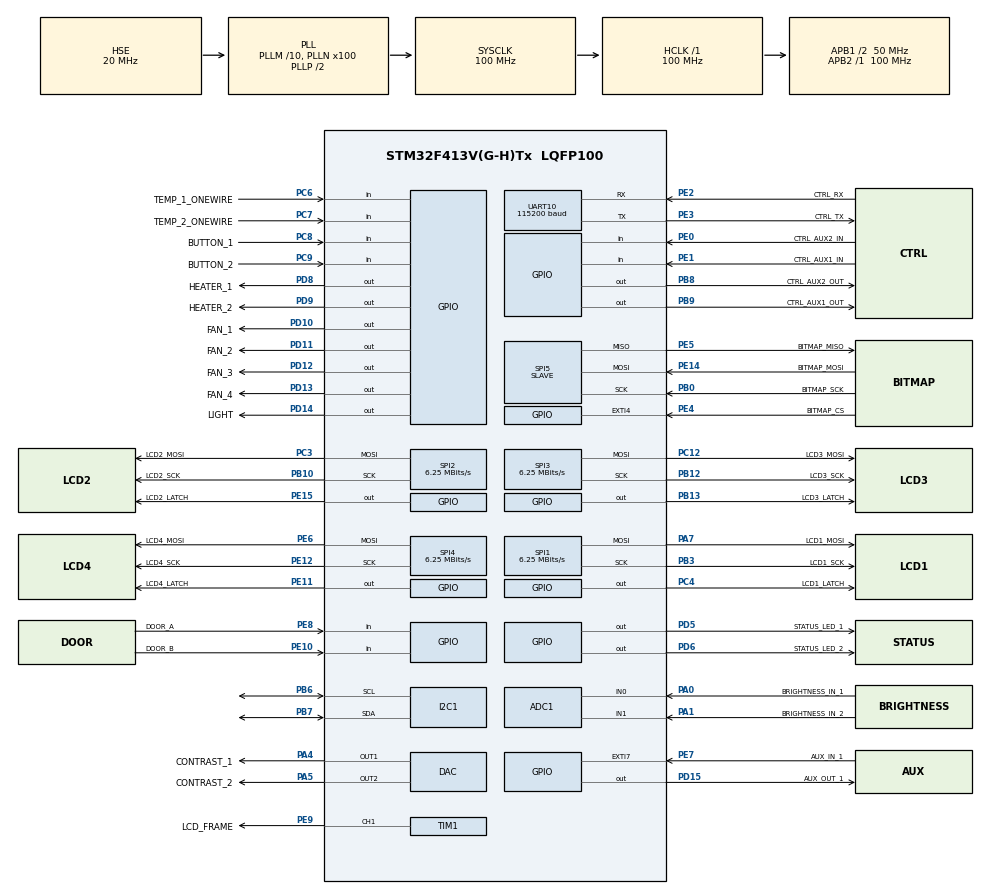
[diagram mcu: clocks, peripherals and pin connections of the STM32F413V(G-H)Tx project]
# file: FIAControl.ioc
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Dma.SPI3_TX.2.MemInc=DMA_MINC_ENABLE
VP_TIM5_VS_ClockSourceINT.Mode=Internal
PD12.GPIO_Label=FAN_3
Dma.SPI1_TX.0.PeriphInc=DMA_PINC_DISABLE
SPI3.Direction=SPI_DIRECTION_2LINES
SPI4.VirtualType=VM_MASTER
SPI3.VirtualType=VM_MASTER
NVIC.I2C1_EV_IRQn=true\:0\:0\:false\:false\:true\:true\:true
Dma.UART10_RX.6.Direction=DMA_PERIPH_TO_MEMORY
SPI1.VirtualType=VM_MASTER
SPI2.VirtualType=VM_MASTER
VP_ADC1_TempSens_Input.Mode=IN-TempSens
PB10.Mode=TX_Only_Simplex_Unidirect_Master
PC12.Signal=SPI3_MOSI
PE8.GPIO_PuPd=GPIO_PULLUP
Dma.SPI5_RX.4.Priority=DMA_PRIORITY_VERY_HIGH
PC6.GPIO_Label=TEMP_1_ONEWIRE
PE10.GPIO_PuPd=GPIO_PULLUP
Dma.SPI5_RX.4.MemDataAlignment=DMA_MDATAALIGN_BYTE
PB13.Signal=GPIO_Output
PD6.GPIO_Label=STATUS_LED_2
PE6.GPIO_Label=LCD4_MOSI
Dma.SPI5_RX.4.FIFOMode=DMA_FIFOMODE_DISABLE
RCC.SYSCLKSource=RCC_SYSCLKSOURCE_PLLCLK
Dma.UART10_RX.6.Instance=DMA2_Stream0
UART10.BaudRate=115200
NVIC.TIM5_IRQn=true\:2\:0\:true\:false\:true\:true\:true
SPI1.Direction=SPI_DIRECTION_2LINES
Dma.UART10_TX.7.PeriphDataAlignment=DMA_PDATAALIGN_BYTE
PE2.Mode=Asynchronous
RCC.APB2TimFreq_Value=100000000
Dma.SPI3_TX.2.PeriphDataAlignment=DMA_PDATAALIGN_BYTE
PB6.Signal=I2C1_SCL
ADC1.Channel-2\#ChannelRegularConversion=ADC_CHANNEL_TEMPSENSOR
PC7.Signal=GPIO_Input
PB6.Mode=I2C
SPI1.CalculateBaudRate=6.25 MBits/s
PC3.Signal=SPI2_MOSI
PD8.Signal=GPIO_Output
Dma.UART10_TX.7.Priority=DMA_PRIORITY_LOW
PE5.Signal=SPI5_MISO
PE1.Signal=GPIO_Input
PB3.Mode=TX_Only_Simplex_Unidirect_Master
ADC1.ScanConvMode=ENABLE
PB12.GPIO_Label=LCD3_SCK
PC4.GPIO_Label=LCD1_LATCH
TIM1.Channel-PWM\ Generation1\ CH1=TIM_CHANNEL_1
PE9.Signal=S_TIM1_CH1
PE4.GPIO_Label=BITMAP_CS
SPI2.CalculateBaudRate=6.25 MBits/s
PE2.Signal=UART10_RX
TIM4.Period=50000
Dma.SPI3_TX.2.Direction=DMA_MEMORY_TO_PERIPH
NVIC.I2C1_ER_IRQn=true\:0\:0\:false\:false\:true\:true\:true
PE10.Signal=GPIO_Input
ADC1.SamplingTime-0\#ChannelRegularConversion=ADC_SAMPLETIME_480CYCLES
PA0.Signal=ADCx_IN0
Dma.SPI2_TX.1.FIFOMode=DMA_FIFOMODE_DISABLE
Dma.SPI1_TX.0.Mode=DMA_NORMAL
Mcu.Package=LQFP100
PB9.Signal=GPIO_Output
TIM2.Prescaler=99
SPI2.Mode=SPI_MODE_MASTER
SPI3.Mode=SPI_MODE_MASTER
PD12.Signal=GPIO_Output
PE12.GPIO_Label=LCD4_SCK
PC6.GPIO_PuPd=GPIO_PULLUP
Dma.SPI2_TX.1.Instance=DMA1_Stream4
NVIC.DMA2_Stream2_IRQn=true\:0\:0\:true\:false\:true\:false\:true
RCC.APB1TimFreq_Value=100000000
Dma.ADC1.5.MemDataAlignment=DMA_MDATAALIGN_WORD
TIM1.Period=LCD_FR_INTERVAL
PE10.GPIO_Label=DOOR_B
PD6.GPIO_ModeDefaultOutputPP=GPIO_MODE_OUTPUT_OD
PA4.GPIO_Label=CONTRAST_1
ADC1.EOCSelection=ADC_EOC_SINGLE_CONV
PD15.Signal=GPIO_Output
SPI5.VirtualType=VM_SLAVE
Dma.UART10_RX.6.Priority=DMA_PRIORITY_HIGH
NVIC.UART10_IRQn=true\:1\:0\:true\:false\:true\:true\:true
PE12.Mode=TX_Only_Simplex_Unidirect_Master
Dma.SPI2_TX.1.MemInc=DMA_MINC_ENABLE
NVIC.EXTI4_IRQn=true\:0\:0\:false\:false\:true\:true\:true
Dma.SPI4_TX.3.MemDataAlignment=DMA_MDATAALIGN_BYTE
Dma.UART10_RX.6.Mode=DMA_CIRCULAR
ADC1.Rank-0\#ChannelRegularConversion=1
PD9.GPIO_Label=HEATER_2
PH1\ -\ OSC_OUT.Mode=HSE-External-Oscillator
PC6.Signal=GPIO_Input
Dma.UART10_RX.6.MemDataAlignment=DMA_MDATAALIGN_BYTE
SPI1.CLKPhase=SPI_PHASE_2EDGE
NVIC.DMA2_Stream1_IRQn=true\:0\:0\:true\:false\:true\:false\:true
RCC.APB1CLKDivider=RCC_HCLK_DIV2
Dma.SPI4_TX.3.FIFOMode=DMA_FIFOMODE_DISABLE
PD10.Signal=GPIO_Output
PB8.GPIO_Label=CTRL_AUX2_OUT
Dma.SPI1_TX.0.FIFOMode=DMA_FIFOMODE_DISABLE
PE8.GPIO_Label=DOOR_A
PC7.GPIO_PuPd=GPIO_PULLUP
Dma.UART10_RX.6.FIFOMode=DMA_FIFOMODE_DISABLE
PE9.GPIO_Label=LCD_FRAME
PB10.Signal=SPI2_SCK
Dma.UART10_TX.7.Direction=DMA_MEMORY_TO_PERIPH
PA5.Signal=COMP_DAC2_group
PC12.Mode=TX_Only_Simplex_Unidirect_Master
PH1\ -\ OSC_OUT.Signal=RCC_OSC_OUT
PE1.GPIO_Label=CTRL_AUX1_IN
Dma.SPI5_RX.4.Instance=DMA2_Stream3
NVIC.TIM3_IRQn=true\:2\:0\:true\:false\:true\:true\:true
PE14.Signal=SPI5_MOSI
PE6.Mode=TX_Only_Simplex_Unidirect_Master
PE15.Signal=GPIO_Output
Dma.SPI2_TX.1.PeriphDataAlignment=DMA_PDATAALIGN_BYTE
PE8.Signal=GPIO_Input
SPI1.Mode=SPI_MODE_MASTER
Dma.SPI2_TX.1.Priority=DMA_PRIORITY_VERY_HIGH
Dma.UART10_TX.7.Instance=DMA2_Stream5
PA1.GPIO_Label=BRIGHTNESS_IN_2
PC9.GPIO_PuPd=GPIO_PULLUP
Dma.SPI1_TX.0.Instance=DMA2_Stream2
ADC1.DMAContinuousRequests=ENABLE
TIM2.Period=65535
UART10.VirtualMode=Asynchronous
PA13.Mode=Serial_Wire
UART10.Mode=MODE_TX_RX
Dma.UART10_TX.7.Mode=DMA_NORMAL
NVIC.DMA2_Stream4_IRQn=true\:0\:0\:true\:false\:true\:false\:true
PC7.GPIO_Label=TEMP_2_ONEWIRE
PC8.GPIO_PuPd=GPIO_PULLUP
PA4.Signal=COMP_DAC1_group
ADC1.SamplingTime-1\#ChannelRegularConversion=ADC_SAMPLETIME_480CYCLES
ADC1.master=1
PA5.GPIO_Label=CONTRAST_2
Dma.SPI5_RX.4.PeriphDataAlignment=DMA_PDATAALIGN_BYTE
PD11.Signal=GPIO_Output
PE5.GPIO_Label=BITMAP_MISO
PC12.GPIO_Label=LCD3_MOSI
ADC1.Rank-1\#ChannelRegularConversion=2
Dma.SPI4_TX.3.Instance=DMA2_Stream1
Dma.ADC1.5.PeriphDataAlignment=DMA_PDATAALIGN_WORD
ProjectManager.HeapSize=0x200
Dma.SPI3_TX.2.PeriphInc=DMA_PINC_DISABLE
Dma.SPI4_TX.3.Direction=DMA_MEMORY_TO_PERIPH
SPI4.CLKPhase=SPI_PHASE_2EDGE
VP_TIM4_VS_ClockSourceINT.Mode=Internal
NVIC.PriorityGroup=NVIC_PRIORITYGROUP_4
PE3.Signal=UART10_TX
PC3.GPIO_Label=LCD2_MOSI
PD5.GPIO_ModeDefaultOutputPP=GPIO_MODE_OUTPUT_OD
Dma.ADC1.5.FIFOMode=DMA_FIFOMODE_DISABLE
PB0.Signal=SPI5_SCK
Dma.UART10_RX.6.PeriphInc=DMA_PINC_DISABLE
Dma.ADC1.5.Instance=DMA2_Stream4
Dma.SPI2_TX.1.MemDataAlignment=DMA_MDATAALIGN_BYTE
Dma.SPI5_RX.4.Direction=DMA_PERIPH_TO_MEMORY
Dma.UART10_TX.7.FIFOMode=DMA_FIFOMODE_DISABLE
Mcu.Family=STM32F4
PC3.Mode=TX_Only_Simplex_Unidirect_Master
Dma.SPI1_TX.0.MemInc=DMA_MINC_ENABLE
PE7.GPIO_PuPd=GPIO_PULLUP
RCC.CortexFreq_Value=100000000
Dma.UART10_TX.7.PeriphInc=DMA_PINC_DISABLE
Dma.SPI3_TX.2.Instance=DMA1_Stream5
ADC1.ContinuousConvMode=ENABLE
PE11.GPIO_Label=LCD4_LATCH
VP_IWDG_VS_IWDG.Mode=IWDG_Activate
SPI4.Direction=SPI_DIRECTION_2LINES
PA0.GPIO_Label=BRIGHTNESS_IN_1
Dma.SPI2_TX.1.PeriphInc=DMA_PINC_DISABLE
PB0.GPIO_Label=BITMAP_SCK
TIM1.Pulse-PWM\ Generation1\ CH1=LCD_FR_INTERVAL/2
PB13.GPIO_Label=LCD3_LATCH
Dma.SPI3_TX.2.Mode=DMA_NORMAL
NVIC.DMA1_Stream4_IRQn=true\:0\:0\:true\:false\:true\:false\:true
ProjectManager.StackSize=0x400
SH.COMP_DAC2_group.0=DAC_OUT2,DAC_OUT2
Dma.SPI5_RX.4.MemInc=DMA_MINC_ENABLE
PD13.Signal=GPIO_Output
TIM1.Prescaler=199
SPI1.CLKPolarity=SPI_POLARITY_LOW
Dma.SPI4_TX.3.PeriphDataAlignment=DMA_PDATAALIGN_BYTE
PH0\ -\ OSC_IN.Signal=RCC_OSC_IN
SPI4.Mode=SPI_MODE_MASTER
PD11.GPIO_Label=FAN_2
RCC.HCLKFreq_Value=100000000
TIM3.Period=625
NVIC.DMA2_Stream0_IRQn=true\:0\:0\:true\:false\:true\:false\:true
RCC.AHBFreq_Value=100000000
SPI2.BaudRatePrescaler=SPI_BAUDRATEPRESCALER_8
ADC1.Channel-0\#ChannelRegularConversion=ADC_CHANNEL_0
RCC.HSE_VALUE=20000000
Dma.SPI4_TX.3.PeriphInc=DMA_PINC_DISABLE
ADC1.Rank-2\#ChannelRegularConversion=3
PA14.Mode=Serial_Wire
TIM3.Prescaler=9999
PB7.Signal=I2C1_SDA
SH.ADCx_IN0.0=ADC1_IN0,IN0
Dma.SPI3_TX.2.Priority=DMA_PRIORITY_VERY_HIGH
PE4.Signal=GPXTI4
SPI4.BaudRatePrescaler=SPI_BAUDRATEPRESCALER_16
Dma.SPI3_TX.2.FIFOMode=DMA_FIFOMODE_DISABLE
PD13.GPIO_Label=FAN_4
PB12.Mode=TX_Only_Simplex_Unidirect_Master
Dma.SPI2_TX.1.Mode=DMA_NORMAL
PD5.GPIO_Label=STATUS_LED_1
IWDG.Reload=4095
SPI2.CLKPhase=SPI_PHASE_2EDGE
PE0.GPIO_Label=CTRL_AUX2_IN
SH.ADCx_IN1.0=ADC1_IN1,IN1
Dma.ADC1.5.PeriphInc=DMA_PINC_DISABLE
Dma.Request2=SPI3_TX
Dma.Request1=SPI2_TX
Dma.SPI5_RX.4.PeriphInc=DMA_PINC_DISABLE
Dma.Request4=SPI5_RX
Dma.UART10_TX.7.MemInc=DMA_MINC_ENABLE
Dma.Request3=SPI4_TX
Dma.Request6=UART10_RX
Dma.Request5=ADC1
SPI2.Direction=SPI_DIRECTION_2LINES
Dma.Request7=UART10_TX
PE7.Signal=GPXTI7
Dma.UART10_RX.6.MemInc=DMA_MINC_ENABLE
PD6.Signal=GPIO_Output
Dma.Request0=SPI1_TX
SPI1.BaudRatePrescaler=SPI_BAUDRATEPRESCALER_16
PE2.GPIO_Label=CTRL_RX
PE3.Mode=Asynchronous
VP_TIM3_VS_ClockSourceINT.Mode=Internal
PB3.GPIO_Label=LCD1_SCK
RCC.PLLSourceVirtual=RCC_PLLSOURCE_HSE
SH.COMP_DAC1_group.0=DAC_OUT1,DAC_OUT1
PD15.GPIO_Label=AUX_OUT_1
TIM3.CounterMode=TIM_COUNTERMODE_UP
PA7.Mode=TX_Only_Simplex_Unidirect_Master
PB9.GPIO_Label=CTRL_AUX1_OUT
PC9.GPIO_Label=BUTTON_2
Dma.SPI4_TX.3.MemInc=DMA_MINC_ENABLE
PC8.Signal=GPIO_Input
PC4.Signal=GPIO_Output
PE4.GPIO_ModeDefaultEXTI=GPIO_MODE_IT_RISING_FALLING
Dma.SPI4_TX.3.Mode=DMA_NORMAL
PE14.GPIO_Label=BITMAP_MOSI
PD9.Signal=GPIO_Output
PD5.Signal=GPIO_Output
Dma.SPI4_TX.3.Priority=DMA_PRIORITY_VERY_HIGH
Dma.ADC1.5.Direction=DMA_PERIPH_TO_MEMORY
SPI5.Mode=SPI_MODE_SLAVE
ADC1.SamplingTime-2\#ChannelRegularConversion=ADC_SAMPLETIME_480CYCLES
TIM1.ClockDivision=TIM_CLOCKDIVISION_DIV1
PD8.GPIO_Label=HEATER_1
PC8.GPIO_Label=BUTTON_1
PA13.Signal=SYS_JTMS-SWDIO
PH0\ -\ OSC_IN.Mode=HSE-External-Oscillator
SH.S_TIM1_CH1.0=TIM1_CH1,PWM Generation1 CH1
PE15.GPIO_Label=LCD2_LATCH
ProjectManager.TargetToolchain=Makefile
PB10.GPIO_Label=LCD2_SCK
NVIC.DMA1_Stream5_IRQn=true\:0\:0\:true\:false\:true\:false\:true
Dma.SPI1_TX.0.PeriphDataAlignment=DMA_PDATAALIGN_BYTE
Dma.SPI1_TX.0.Direction=DMA_MEMORY_TO_PERIPH
Dma.UART10_RX.6.PeriphDataAlignment=DMA_PDATAALIGN_BYTE
ADC1.Channel-1\#ChannelRegularConversion=ADC_CHANNEL_1
RCC.USBFreq_Value=100000000
PD10.GPIO_Label=FAN_1
NVIC.DMA2_Stream3_IRQn=true\:0\:0\:true\:false\:true\:false\:true
TIM4.Prescaler=9999
PE11.Signal=GPIO_Output
PA1.Signal=ADCx_IN1
Dma.ADC1.5.Priority=DMA_PRIORITY_MEDIUM
PB0.Mode=Full_Duplex_Slave
board=custom
SPI3.CLKPhase=SPI_PHASE_2EDGE
Dma.SPI2_TX.1.Direction=DMA_MEMORY_TO_PERIPH
RCC.VCOOutputFreq_Value=200000000
RCC.APB2Freq_Value=100000000
SPI3.CalculateBaudRate=6.25 MBits/s
UART10.OverSampling=UART_OVERSAMPLING_8
VP_TIM2_VS_ClockSourceINT.Mode=Internal
PE14.Mode=Full_Duplex_Slave
Dma.SPI3_TX.2.MemDataAlignment=DMA_MDATAALIGN_BYTE
PE5.Mode=Full_Duplex_Slave
NVIC.DMA2_Stream5_IRQn=true\:0\:0\:false\:false\:true\:false\:true
SPI3.BaudRatePrescaler=SPI_BAUDRATEPRESCALER_8
PE7.GPIO_ModeDefaultEXTI=GPIO_MODE_IT_RISING_FALLING
SPI4.CalculateBaudRate=6.25 MBits/s
PD14.GPIO_Label=LIGHT
PE6.Signal=SPI4_MOSI
ADC1.NbrOfConversion=3
Mcu.Name=STM32F413V(G-H)Tx
PE0.Signal=GPIO_Input
PE7.GPIO_Label=AUX_IN_1
PE12.Signal=SPI4_SCK
PD14.Signal=GPIO_Output
PB3.Signal=SPI1_SCK
RCC.SYSCLKFreq_VALUE=100000000
PA7.GPIO_Label=LCD1_MOSI
TIM5.Prescaler=999
PB7.Mode=I2C
Dma.ADC1.5.MemInc=DMA_MINC_ENABLE
NVIC.EXTI9_5_IRQn=true\:0\:0\:false\:false\:true\:true\:true
PA14.Signal=SYS_JTCK-SWCLK
Dma.SPI1_TX.0.MemDataAlignment=DMA_MDATAALIGN_BYTE
Dma.SPI1_TX.0.Priority=DMA_PRIORITY_VERY_HIGH
Dma.SPI5_RX.4.Mode=DMA_NORMAL
Dma.UART10_TX.7.MemDataAlignment=DMA_MDATAALIGN_BYTE
ADC1.NbrOfConversionFlag=1
RCC.PLLM=10
RCC.PLLN=100
IWDG.Prescaler=IWDG_PRESCALER_4
PB8.Signal=GPIO_Output
PE3.GPIO_Label=CTRL_TX
TIM5.Period=1000
PC9.Signal=GPIO_Input
NVIC.TIM4_IRQn=true\:2\:0\:true\:false\:true\:true\:true
RCC.APB1Freq_Value=50000000
PD8.PinState=GPIO_PIN_RESET
ADC1.ClockPrescaler=ADC_CLOCK_SYNC_PCLK_DIV8
PB12.Signal=SPI3_SCK
Dma.ADC1.5.Mode=DMA_CIRCULAR
SPI5.Direction=SPI_DIRECTION_2LINES
PA7.Signal=SPI1_MOSI

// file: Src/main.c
/* USER CODE BEGIN Header */
/**
 ******************************************************************************
 * @file           : main.c
 * @brief          : Main program body
 ******************************************************************************
 * @attention
 *
 * <h2><center>&copy; Copyright (c) 2020 STMicroelectronics.
 * All rights reserved.</center></h2>
 *
 * This software component is licensed by ST under BSD 3-Clause license,
 * the "License"; You may not use this file except in compliance with the
 * License. You may obtain a copy of the License at:
 *                        opensource.org/licenses/BSD-3-Clause
 *
 ******************************************************************************
 */
/* USER CODE END Header */

#include "main.h"
#include "adc.h"
#include "dac.h"
#include "dma.h"
#include "i2c.h"
#include "iwdg.h"
#include "spi.h"
#include "tim.h"
#include "usart.h"
#include "gpio.h"

/* USER CODE BEGIN Includes */
#include "fia.h"
/* USER CODE END Includes */

void SystemClock_Config(void);

int main(void)
{
  /* USER CODE BEGIN 1 */
  // Stop IWDT when halting core during debugging
  // Doesn't seem to be necessary though
  //__HAL_DBGMCU_FREEZE_IWDG();
  /* USER CODE END 1 */

  /* MCU Configuration--------------------------------------------------------*/

  /* Reset of all peripherals, Initializes the Flash interface and the Systick. */
  HAL_Init();

  /* Configure the system clock */
  SystemClock_Config();

  /* Initialize all configured peripherals */
  MX_GPIO_Init();
  MX_DMA_Init();
  MX_ADC1_Init();
  MX_DAC_Init();
  MX_I2C1_Init();
  MX_SPI1_Init();
  MX_SPI2_Init();
  MX_SPI3_Init();
  MX_SPI4_Init();
  MX_SPI5_Init();
  MX_TIM1_Init();
  MX_UART10_Init();
  MX_TIM2_Init();
  MX_TIM3_Init();
  MX_TIM4_Init();
  MX_IWDG_Init();
  MX_TIM5_Init();
  /* USER CODE BEGIN 2 */
    FIA_Init();
  /* USER CODE END 2 */

  /* Infinite loop */
    while (1) {

    /* USER CODE BEGIN 3 */
        FIA_MainLoop();
    }
  /* USER CODE END 3 */
}

void SystemClock_Config(void)
{
  RCC_OscInitTypeDef RCC_OscInitStruct = {0};
  RCC_ClkInitTypeDef RCC_ClkInitStruct = {0};

  /** Configure the main internal regulator output voltage
  */
  __HAL_RCC_PWR_CLK_ENABLE();
  __HAL_PWR_VOLTAGESCALING_CONFIG(PWR_REGULATOR_VOLTAGE_SCALE1);
  /** Initializes the CPU, AHB and APB busses clocks
  */
  RCC_OscInitStruct.OscillatorType = RCC_OSCILLATORTYPE_LSI|RCC_OSCILLATORTYPE_HSE;
  RCC_OscInitStruct.HSEState = RCC_HSE_ON;
  RCC_OscInitStruct.LSIState = RCC_LSI_ON;
  RCC_OscInitStruct.PLL.PLLState = RCC_PLL_ON;
  RCC_OscInitStruct.PLL.PLLSource = RCC_PLLSOURCE_HSE;
  RCC_OscInitStruct.PLL.PLLM = 10;
  RCC_OscInitStruct.PLL.PLLN = 100;
  RCC_OscInitStruct.PLL.PLLP = RCC_PLLP_DIV2;
  RCC_OscInitStruct.PLL.PLLQ = 2;
  RCC_OscInitStruct.PLL.PLLR = 2;
  if (HAL_RCC_OscConfig(&RCC_OscInitStruct) != HAL_OK)
  {
    Error_Handler();
  }
  /** Initializes the CPU, AHB and APB busses clocks
  */
  RCC_ClkInitStruct.ClockType = RCC_CLOCKTYPE_HCLK|RCC_CLOCKTYPE_SYSCLK
                              |RCC_CLOCKTYPE_PCLK1|RCC_CLOCKTYPE_PCLK2;
  RCC_ClkInitStruct.SYSCLKSource = RCC_SYSCLKSOURCE_PLLCLK;
  RCC_ClkInitStruct.AHBCLKDivider = RCC_SYSCLK_DIV1;
  RCC_ClkInitStruct.APB1CLKDivider = RCC_HCLK_DIV2;
  RCC_ClkInitStruct.APB2CLKDivider = RCC_HCLK_DIV1;

  if (HAL_RCC_ClockConfig(&RCC_ClkInitStruct, FLASH_LATENCY_3) != HAL_OK)
  {
    Error_Handler();
  }
}

void Error_Handler(void)
{
}

/************************ (C) COPYRIGHT STMicroelectronics *****END OF FILE****/
